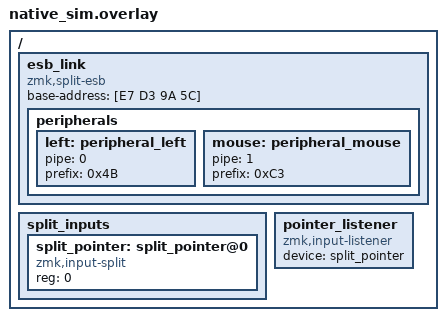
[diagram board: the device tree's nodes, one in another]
/ {
    esb_link {
        compatible = "zmk,split-esb";
        base-address = [E7 D3 9A 5C];

        peripherals {
            left: peripheral_left {
                pipe = <0>;
                prefix = <0x4B>;
            };

            mouse: peripheral_mouse {
                pipe = <1>;
                prefix = <0xC3>;
            };
        };
    };

    split_inputs {
        #address-cells = <1>;
        #size-cells = <0>;

        split_pointer: split_pointer@0 {
            compatible = "zmk,input-split";
            reg = <0>;
        };
    };

    pointer_listener {
        compatible = "zmk,input-listener";
        device = <&split_pointer>;
    };
};
